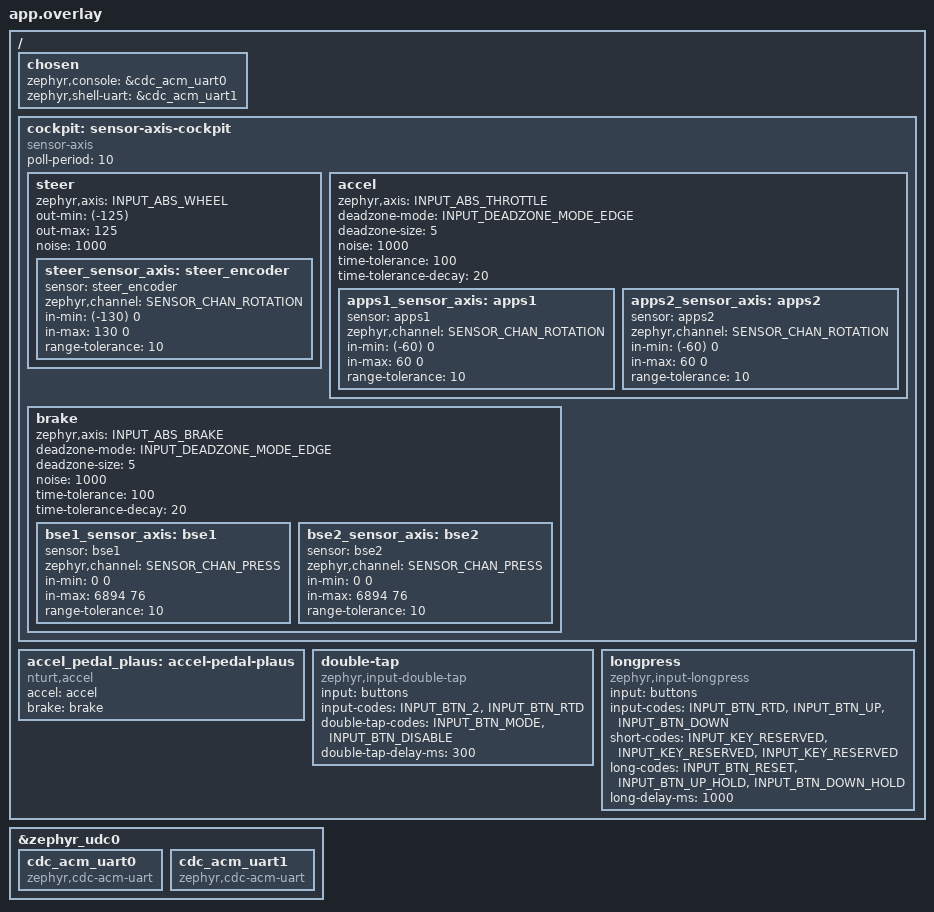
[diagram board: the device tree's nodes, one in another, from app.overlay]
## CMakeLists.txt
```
cmake_minimum_required(VERSION 3.20.0)
set(CMAKE_C_STANDARD 11)

find_package(Zephyr REQUIRED HINTS $ENV{ZEPHYR_BASE})

project(nturt_vcu LANGUAGES C)

zephyr_include_directories(
    include
)

add_subdirectory(src/canopen)
add_subdirectory(src/ctrl)
add_subdirectory(src/dashboard)
add_subdirectory(src/msg)
add_subdirectory(src/perception)
add_subdirectory(src/sys)
add_subdirectory(src/telemetry)

target_sources(app PRIVATE
    src/main.c
)
```

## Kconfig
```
menuconfig VCU
	bool "NTURT Vehicle Control Unit (VCU)"
	default y
	select NTURT

if VCU

rsource "Kconfig.hardware"

rsource "src/canopen/Kconfig"
rsource "src/ctrl/Kconfig"
rsource "src/dashboard/Kconfig"
rsource "src/msg/Kconfig"
rsource "src/perception/Kconfig"
rsource "src/sys/Kconfig"
rsource "src/telemetry/Kconfig"

config VCU_HIL
	bool "VCU hardware in a loop test"
	depends on VCU_CANOPEN

if VCU_HIL

choice VCU_SOURCE_COCKPIT
	default VCU_SOURCE_COCKPIT_CANOPEN
endchoice
choice VCU_SOURCE_IMU
	default VCU_SOURCE_IMU_CANOPEN
endchoice
choice VCU_SOURCE_GPS
	default VCU_SOURCE_GPS_CANOPEN
endchoice

endif # VCU_HIL

choice VCU_SOURCE_COCKPIT
	prompt "Cockpit sensors data source"
	default VCU_SOURCE_COCKPIT_NATIVE if VCU_SENSORS
	default VCU_SOURCE_COCKPIT_CANOPEN if VCU_CANOPEN
	default VCU_SOURCE_COCKPIT_DISABLED

config VCU_SOURCE_COCKPIT_DISABLED
	bool "Cockpit data disabled"

config VCU_SOURCE_COCKPIT_NATIVE
	bool "Cockpit data from natively controlled sensors"
	depends on VCU_SENSORS

config VCU_SOURCE_COCKPIT_CANOPEN
	bool "Cockpit data from CAN open"
	depends on VCU_CANOPEN

endchoice # VCU_SOURCE_COCKPIT

choice VCU_SOURCE_IMU
	prompt "IMU data source"
	default VCU_SOURCE_IMU_NATIVE if VCU_HAS_IMU
	default VCU_SOURCE_IMU_CANOPEN if VCU_CANOPEN
	default VCU_SOURCE_IMU_DISABLED

config VCU_SOURCE_IMU_DISABLED
	bool "IMU data disabled"

config VCU_SOURCE_IMU_NATIVE
	bool "IMU data from natively controlled sensors"
	depends on VCU_HAS_IMU

config VCU_SOURCE_IMU_CANOPEN
	bool "IMU data from CAN open"
	depends on VCU_CANOPEN

endchoice # VCU_SOURCE_IMU

choice VCU_SOURCE_GPS
	prompt "GPS data source"
	default VCU_SOURCE_GPS_NATIVE if VCU_HAS_GPS
	default VCU_SOURCE_GPS_CANOPEN if VCU_CANOPEN
	default VCU_SOURCE_GPS_DISABLED

config VCU_SOURCE_GPS_DISABLED
	bool "GPS data disabled"

config VCU_SOURCE_GPS_NATIVE
	bool "GPS data from natively controlled sensors"
	depends on VCU_HAS_GPS

config VCU_SOURCE_GPS_CANOPEN
	bool "GPS data from CAN open"
	depends on VCU_CANOPEN

endchoice # VCU_SOURCE_GPS

choice VCU_SOURCE_STATES
	prompt "Vehicle control states data source"
	default VCU_SOURCE_STATES_FUSION

config VCU_SOURCE_STATES_DISABLED
	bool "Vehicle states data disabled"

config VCU_SOURCE_STATES_FUSION
	bool "Vehicle states data from sensor fusion"

config VCU_SOURCE_STATES_CANOPEN
	bool "Vehicle states data from CAN open"
	depends on VCU_CANOPEN

endchoice # VCU_SOURCE_STATES

endif # VCU

menu "Zephyr"
source "Kconfig.zephyr"
endmenu # "Zephyr"
```

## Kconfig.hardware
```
DT_CHOSEN_NTURT_BRAKE_LIGHT := nturt,brake_light
config VCU_HAS_BRAKE_LIGHT
	bool
	depends on $(dt_chosen_enabled,$(DT_CHOSEN_NTURT_BRAKE_LIGHT))
	default y

DT_CHOSEN_NTURT_IMU := nturt,imu
config VCU_HAS_IMU
	bool
	depends on $(dt_chosen_enabled,$(DT_CHOSEN_NTURT_IMU))
	default y

DT_CHOSEN_NTURT_GPS := nturt,gps
config VCU_HAS_GPS
	bool
	depends on $(dt_chosen_enabled,$(DT_CHOSEN_NTURT_GPS))
	default y

DT_CHOSEN_NTURT_SUSP_FL := nturt,susp-fl
config VCU_HAS_SUSP_FL
	bool
	depends on $(dt_chosen_enabled,$(DT_CHOSEN_NTURT_SUSP_FL))
	default y

DT_CHOSEN_NTURT_SUSP_FR := nturt,susp-fr
config VCU_HAS_SUSP_FR
	bool
	depends on $(dt_chosen_enabled,$(DT_CHOSEN_NTURT_SUSP_FR))
	default y

DT_CHOSEN_NTURT_SUSP_RL := nturt,susp-rl
config VCU_HAS_SUSP_RL
	bool
	depends on $(dt_chosen_enabled,$(DT_CHOSEN_NTURT_SUSP_RL))
	default y

DT_CHOSEN_NTURT_SUSP_RR := nturt,susp-rr
config VCU_HAS_SUSP_RR
	bool
	depends on $(dt_chosen_enabled,$(DT_CHOSEN_NTURT_SUSP_RR))
	default y

config VCU_HAS_SUSP
	bool
	depends on VCU_HAS_SUSP_FL || VCU_HAS_SUSP_FR || \
		VCU_HAS_SUSP_RL || VCU_HAS_SUSP_RR
	default y

DT_CHOSEN_NTURT_POW_IN_VOLT := nturt,pow-in-volt
config VCU_HAS_POW_IN_VOLT
	bool
	depends on $(dt_chosen_enabled,$(DT_CHOSEN_NTURT_POW_IN_VOLT))
	default y

DT_CHOSEN_NTURT_POW_5V_CURR := nturt,pow-5v-curr
config VCU_HAS_POW_5V_CURR
	bool
	depends on $(dt_chosen_enabled,$(DT_CHOSEN_NTURT_POW_5V_CURR))
	default y

DT_CHOSEN_NTURT_POW_5V_RPI_CURR := nturt,pow-5v-rpi-curr
config VCU_HAS_POW_5V_RPI_CURR
	bool
	depends on $(dt_chosen_enabled,$(DT_CHOSEN_NTURT_POW_5V_RPI_CURR))
	default y

DT_CHOSEN_NTURT_POW_LOW := nturt,pow-low
config VCU_HAS_POW_LOW
	bool
	depends on $(dt_chosen_enabled,$(DT_CHOSEN_NTURT_POW_LOW))
	default y

config VCU_HAS_POW
	bool
	depends on VCU_HAS_POW_IN_VOLT || VCU_HAS_POW_5V_CURR || \
		VCU_HAS_POW_5V_RPI_CURR || VCU_HAS_POW_LOW
	default y
```

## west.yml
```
manifest:
  remotes:
    - name: zephyrproject-rtos
      url-base: https://github.com/zephyrproject-rtos
    - name: nturt
      url-base: https://github.com/NTURacingTeam

  group-filter: [+optional]

  projects:
    - name: zephyr
      remote: nturt
      revision: main
      import: true
    - name: nturt_zephyr_common
      remote: nturt
      revision: master
      import: true
```

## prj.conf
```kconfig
# compiler
CONFIG_DEBUG_OPTIMIZATIONS=y
CONFIG_ASSERT=y

# hardware
CONFIG_FPU=y
CONFIG_DMA=y

# kernel
## debug
CONFIG_DEBUG=y
CONFIG_PRINTK=y

## memory
CONFIG_HEAP_MEM_POOL_SIZE=8192
CONFIG_COMMON_LIBC_MALLOC_ARENA_SIZE=8192

## workqueue
CONFIG_SYSTEM_WORKQUEUE_STACK_SIZE=2048

## logging
CONFIG_LOG=y
CONFIG_LOG_DEFAULT_LEVEL=3
CONFIG_LOG_BUFFER_SIZE=4096
CONFIG_LOG_PROCESS_THREAD_SLEEP_MS=100

## tracing
# CONFIG_TRACING=y

### sysview
# CONFIG_SEGGER_SYSTEMVIEW=y
# CONFIG_SEGGER_SYSVIEW_RTT_BUFFER_SIZE=32768

## main thread
CONFIG_MAIN_STACK_SIZE=4096

# nturt
## usb
CONFIG_NTURT_USB=y
CONFIG_NTURT_USB_PID=0x0001
CONFIG_NTURT_USB_PRODUCT_STRING="Vehicle Control Unit"

# vcu
CONFIG_VCU_SOURCE_IMU_CANOPEN=y
CONFIG_VCU_CTRL_ALGO_DUMB=y
## sys
CONFIG_VCU_SYS=y
CONFIG_VCU_SHELL=y

## message
CONFIG_VCU_MSG=y

## telemetry
CONFIG_VCU_TM=y

## canopen
CONFIG_VCU_CANOPEN=y

## command
# CONFIG_NTURT_CMD=y
# NTURT_CMD_PROCESS_THREAD_PRIORITY=10

## perception
CONFIG_VCU_PERCEPTION=y

## control
CONFIG_VCU_CTRL=y

## dashboard
CONFIG_VCU_DASHBOARD=y

## hil
CONFIG_VCU_HIL=n
```

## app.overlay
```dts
#include <zephyr/dt-bindings/sensor/sensor-channels.h>
#include <zephyr/dt-bindings/input/input-event-codes.h>
#include <zephyr/dt-bindings/input/sensor-axis.h>

#include "vcu/dt-bindings/dashboard.h"

/ {
    // sensing: sensing-node {
    //     compatible = "zephyr,sensing";
        
    //     test: test {
    //         compatible = "zephyr,sensing-phy-generic";
    //         zephyr,channels = <SENSOR_CHAN_DISTANCE>;
    //         friendly-name = "Test sensor";
    //         minimal-interval = <1000>;
    //         underlying-device = <&susp_fl>;
    //     };
    // };

    chosen {
        zephyr,console = &cdc_acm_uart0;
        zephyr,shell-uart = &cdc_acm_uart1;
    };

    cockpit: sensor-axis-cockpit {
        compatible = "sensor-axis";
        poll-period = <10>;

        steer: steer {
            zephyr,axis = <INPUT_ABS_WHEEL>;
            out-min = <(-125)>;
            out-max = <125>;
            noise = <1000>; // 1%

            steer_sensor_axis: steer_encoder {
                sensor = <&steer_encoder>;
                zephyr,channel = <SENSOR_CHAN_ROTATION>;
                in-min = <(-130) 0>;
                in-max = <130 0>;
                range-tolerance = <10>; // 10%
            };
        };

        accel: accel {
            zephyr,axis = <INPUT_ABS_THROTTLE>;
            deadzone-mode = <INPUT_DEADZONE_MODE_EDGE>;
            deadzone-size = <5>; // 5%
            noise = <1000>; // 1%
            // dev-tolerance = <10>; // 10%
            time-tolerance = <100>; // 100ms
            time-tolerance-decay = <20>; // 20%

            apps1_sensor_axis: apps1 {
                sensor = <&apps1>;
                zephyr,channel = <SENSOR_CHAN_ROTATION>;
                in-min = <(-60) 0>;
                in-max = <60 0>;
                range-tolerance = <10>; // 10%
            };

            apps2_sensor_axis: apps2 {
                sensor = <&apps2>;
                zephyr,channel = <SENSOR_CHAN_ROTATION>;
                in-min = <(-60) 0>;
                in-max = <60 0>;
                range-tolerance = <10>; // 10%
                // status = "disabled"; // disable apps2 for now, as it is not used in the current design
            };
        };

        brake: brake {
            zephyr,axis = <INPUT_ABS_BRAKE>;
            deadzone-mode = <INPUT_DEADZONE_MODE_EDGE>;
            deadzone-size = <5>; // 5%
            noise = <1000>; // 1%
            time-tolerance = <100>; // 100ms
            time-tolerance-decay = <20>; // 20%

            bse1_sensor_axis: bse1 {
                sensor = <&bse1>;
                zephyr,channel = <SENSOR_CHAN_PRESS>;
                in-min = <0 0>;
                in-max = <6894 76>;
                range-tolerance = <10>; // 10%
            };

            bse2_sensor_axis: bse2 {
                sensor = <&bse2>;
                zephyr,channel = <SENSOR_CHAN_PRESS>;
                in-min = <0 0>;
                in-max = <6894 76>;
                range-tolerance = <10>; // 10%
            };
        };
    };

    accel_pedal_plaus: accel-pedal-plaus {
        compatible = "nturt,accel";
        accel = <&accel>;
        brake = <&brake>;
    };

    double-tap {
        input = <&buttons>;
        compatible = "zephyr,input-double-tap";
        input-codes = <INPUT_BTN_2>, <INPUT_BTN_RTD>;
        double-tap-codes = <INPUT_BTN_MODE>, <INPUT_BTN_DISABLE>;
        double-tap-delay-ms = <300>;
    };

    longpress {
        input = <&buttons>;
        compatible = "zephyr,input-longpress";
        input-codes = <INPUT_BTN_RTD>, <INPUT_BTN_UP>,
            <INPUT_BTN_DOWN>;
        // ignore short presses using reserved code
        short-codes = <INPUT_KEY_RESERVED>, <INPUT_KEY_RESERVED>,
            <INPUT_KEY_RESERVED>;
        long-codes = <INPUT_BTN_RESET>, <INPUT_BTN_UP_HOLD>,
            <INPUT_BTN_DOWN_HOLD>;
        long-delay-ms = <1000>;
    };
};

&zephyr_udc0 {
    cdc_acm_uart0: cdc_acm_uart0 {
        compatible = "zephyr,cdc-acm-uart";
    };

    cdc_acm_uart1: cdc_acm_uart1 {
        compatible = "zephyr,cdc-acm-uart";
    };
};
```

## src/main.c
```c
// glibc includes
#include <stdbool.h>
#include <stdint.h>
#include <stdio.h>

// zephyr includes
#include <zephyr/drivers/auxdisplay.h>
#include <zephyr/drivers/gpio.h>
#include <zephyr/drivers/led_strip.h>
#include <zephyr/kernel.h>
#include <zephyr/logging/log.h>

// nturt includes
#include <nturt/canbus/canopen.h>
#include <nturt/telemetry.h>

// project includes
#include "vcu/telemetry.h"

LOG_MODULE_REGISTER(main, LOG_LEVEL_INF);

int main() {
  while (true) {
    k_sleep(K_SECONDS(1));
  }

  return 0;
}
```
